# PIC32MX470F512H register map
Registers are 32-bit, access not given, reset 0x0 unless marked. A register's access mark holds for its fields unless they carry their own. Offsets are from the block's base; [hi:lo] are bit positions; {n}, {i} and the like mark numbered series; 'fields as' and 'values as' point back to an identical list.

## ADC10 — ADC10 peripheral
Base 0xBF809000
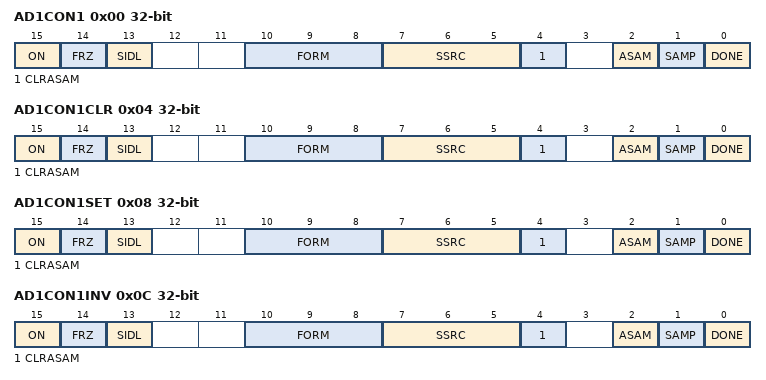
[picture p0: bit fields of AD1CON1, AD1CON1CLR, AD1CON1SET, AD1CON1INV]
0x00 AD1CON1
  [15] ON, [14] FRZ, [13] SIDL, [10:8] FORM, [7:5] SSRC, [4] CLRASAM, [2] ASAM, [1] SAMP, [0] DONE
0x04 AD1CON1CLR
  fields as AD1CON1
0x08 AD1CON1SET
  fields as AD1CON1
0x0C AD1CON1INV
  fields as AD1CON1
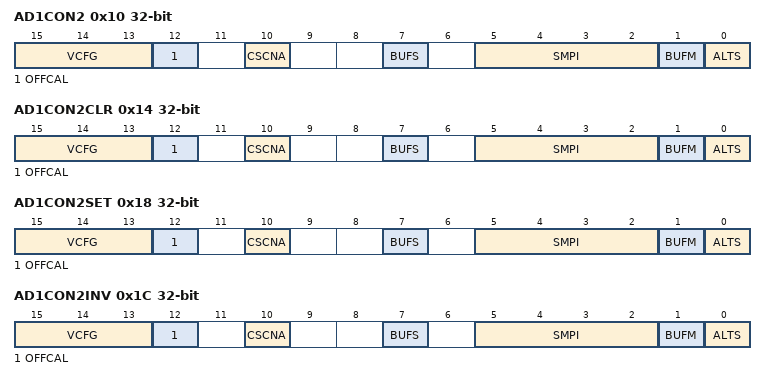
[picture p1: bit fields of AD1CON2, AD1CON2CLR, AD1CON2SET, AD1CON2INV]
0x10 AD1CON2
  [15:13] VCFG, [12] OFFCAL, [10] CSCNA, [7] BUFS, [5:2] SMPI, [1] BUFM, [0] ALTS
0x14 AD1CON2CLR
  fields as AD1CON2
0x18 AD1CON2SET
  fields as AD1CON2
0x1C AD1CON2INV
  fields as AD1CON2
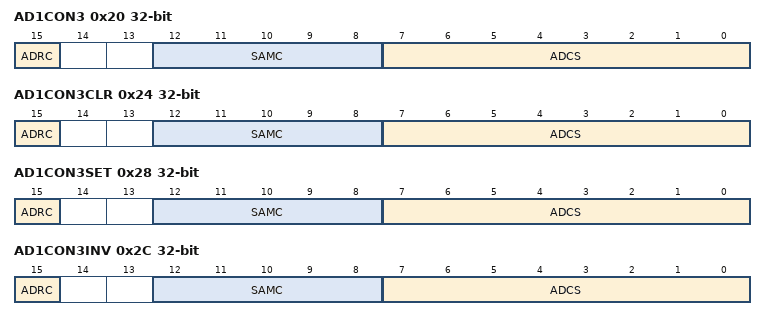
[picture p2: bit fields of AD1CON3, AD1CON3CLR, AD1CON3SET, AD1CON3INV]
0x20 AD1CON3
  [15] ADRC, [12:8] SAMC, [7:0] ADCS
0x24 AD1CON3CLR
  [15] ADRC, [12:8] SAMC, [7:0] ADCS
0x28 AD1CON3SET
  [15] ADRC, [12:8] SAMC, [7:0] ADCS
0x2C AD1CON3INV
  [15] ADRC, [12:8] SAMC, [7:0] ADCS
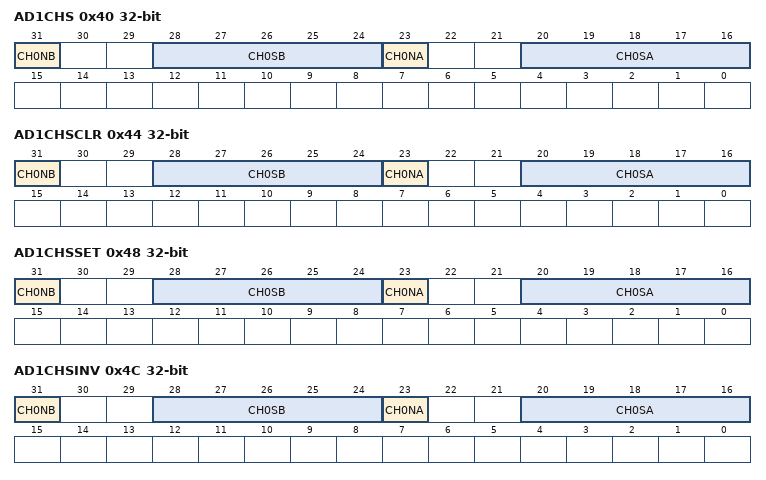
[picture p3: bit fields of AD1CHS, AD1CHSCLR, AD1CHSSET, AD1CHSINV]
0x40 AD1CHS
  [31] CH0NB, [28:24] CH0SB, [23] CH0NA, [20:16] CH0SA
0x44 AD1CHSCLR
  [31] CH0NB, [28:24] CH0SB, [23] CH0NA, [20:16] CH0SA
0x48 AD1CHSSET
  [31] CH0NB, [28:24] CH0SB, [23] CH0NA, [20:16] CH0SA
0x4C AD1CHSINV
  [31] CH0NB, [28:24] CH0SB, [23] CH0NA, [20:16] CH0SA
0x50 AD1CSSL
  [30:0] CSSL
0x54 AD1CSSLCLR
  [30:0] CSSL
0x58 AD1CSSLSET
  [30:0] CSSL
0x5C AD1CSSLINV
  [30:0] CSSL
{0x70+0x10*i} ADC1BUF{i} (i=0..9)
0x110 ADC1BUFA
0x120 ADC1BUFB
0x130 ADC1BUFC
0x140 ADC1BUFD
0x150 ADC1BUFE
0x160 ADC1BUFF

## CVR — CVR peripheral
Base 0xBF809800
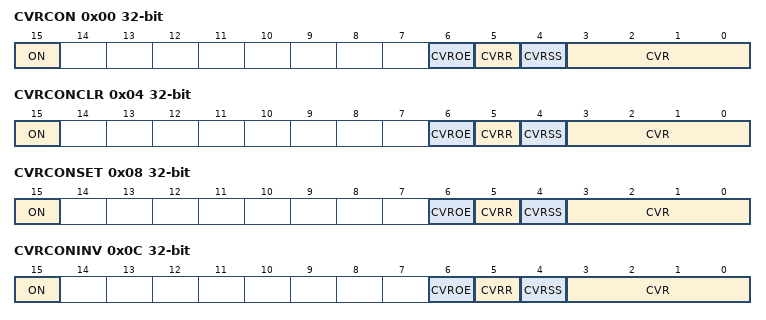
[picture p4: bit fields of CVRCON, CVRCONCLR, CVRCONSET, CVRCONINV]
0x00 CVRCON
  [15] ON, [6] CVROE, [5] CVRR, [4] CVRSS, [3:0] CVR
0x04 CVRCONCLR
  [15] ON, [6] CVROE, [5] CVRR, [4] CVRSS, [3:0] CVR
0x08 CVRCONSET
  [15] ON, [6] CVROE, [5] CVRR, [4] CVRSS, [3:0] CVR
0x0C CVRCONINV
  [15] ON, [6] CVROE, [5] CVRR, [4] CVRSS, [3:0] CVR

## CMP1 — CMP1 peripheral
Base 0xBF80A000
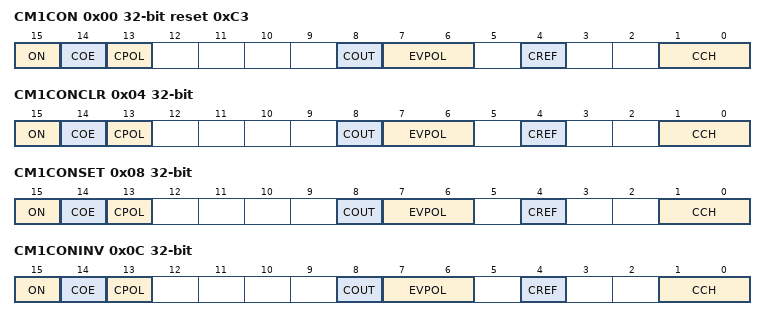
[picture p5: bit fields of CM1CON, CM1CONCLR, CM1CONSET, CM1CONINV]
0x00 CM1CON reset 0xC3
  [15] ON, [14] COE, [13] CPOL, [8] COUT, [7:6] EVPOL, [4] CREF, [1:0] CCH
0x04 CM1CONCLR
  fields as CM1CON
0x08 CM1CONSET
  fields as CM1CON
0x0C CM1CONINV
  fields as CM1CON

## CMP2 — CMP2 peripheral
Base 0xBF80A010
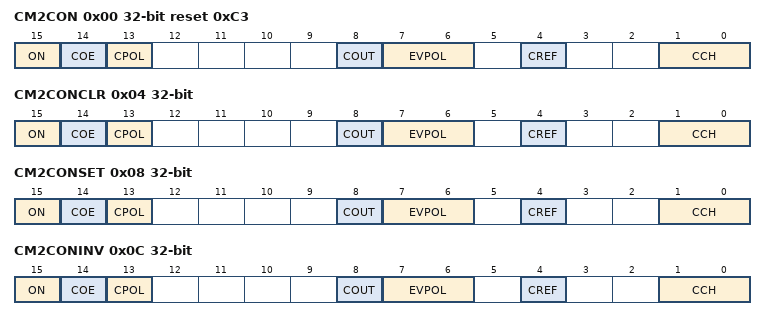
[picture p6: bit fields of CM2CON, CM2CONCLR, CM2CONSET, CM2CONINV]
0x00 CM2CON reset 0xC3
  [15] ON, [14] COE, [13] CPOL, [8] COUT, [7:6] EVPOL, [4] CREF, [1:0] CCH
0x04 CM2CONCLR
  fields as CM2CON
0x08 CM2CONSET
  fields as CM2CON
0x0C CM2CONINV
  fields as CM2CON

## CMP — CMP peripheral
Base 0xBF80A060
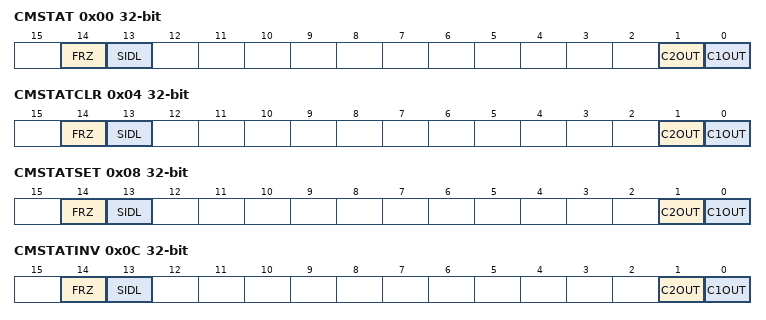
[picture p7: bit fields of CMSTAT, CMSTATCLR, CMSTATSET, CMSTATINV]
0x00 CMSTAT
  [14] FRZ, [13] SIDL, [1] C2OUT, [0] C1OUT
0x04 CMSTATCLR
  [14] FRZ, [13] SIDL, [1] C2OUT, [0] C1OUT
0x08 CMSTATSET
  [14] FRZ, [13] SIDL, [1] C2OUT, [0] C1OUT
0x0C CMSTATINV
  [14] FRZ, [13] SIDL, [1] C2OUT, [0] C1OUT

## CTMU — CTMU peripheral
Base 0xBF80A200
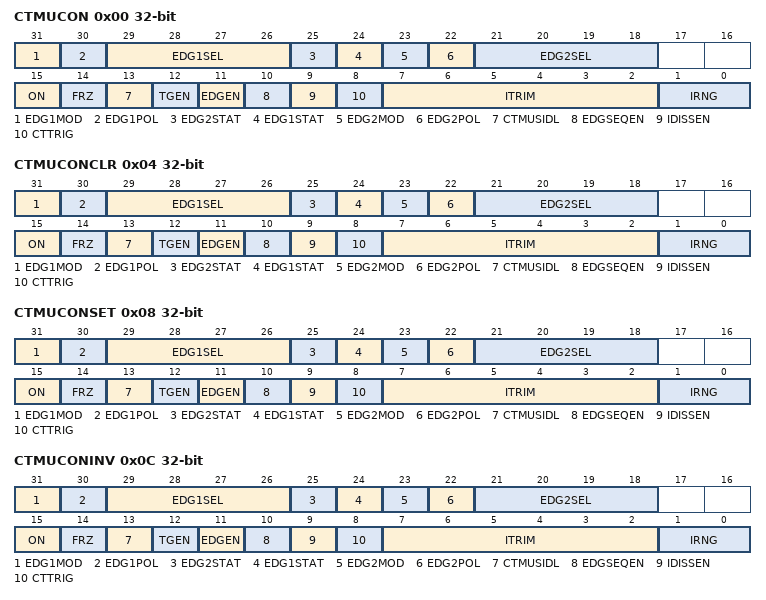
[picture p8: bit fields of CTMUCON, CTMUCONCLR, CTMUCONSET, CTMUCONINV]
0x00 CTMUCON
  [31] EDG1MOD, [30] EDG1POL, [29:26] EDG1SEL, [25] EDG2STAT, [24] EDG1STAT, [23] EDG2MOD, [22] EDG2POL, [21:18] EDG2SEL, [15] ON, [14] FRZ, [13] CTMUSIDL, [12] TGEN, [11] EDGEN, [10] EDGSEQEN, [9] IDISSEN, [8] CTTRIG, [7:2] ITRIM, [1:0] IRNG
0x04 CTMUCONCLR
  fields as CTMUCON
0x08 CTMUCONSET
  fields as CTMUCON
0x0C CTMUCONINV
  fields as CTMUCON

## OSC — OSC peripheral
Base 0xBF80F000
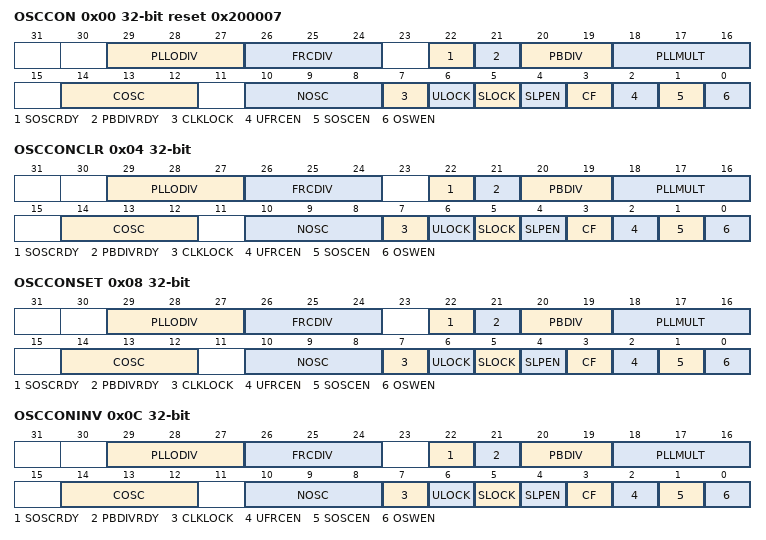
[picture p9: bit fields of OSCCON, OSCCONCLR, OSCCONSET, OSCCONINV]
0x00 OSCCON reset 0x200007
  [29:27] PLLODIV, [26:24] FRCDIV, [22] SOSCRDY, [21] PBDIVRDY, [20:19] PBDIV, [18:16] PLLMULT, [14:12] COSC, [10:8] NOSC, [7] CLKLOCK, [6] ULOCK, [5] SLOCK, [4] SLPEN, [3] CF, [2] UFRCEN, [1] SOSCEN, [0] OSWEN
0x04 OSCCONCLR
  fields as OSCCON
0x08 OSCCONSET
  fields as OSCCON
0x0C OSCCONINV
  fields as OSCCON
0x10 OSCTUN
  [5:0] TUN
0x14 OSCTUNCLR
  [5:0] TUN
0x18 OSCTUNSET
  [5:0] TUN
0x1C OSCTUNINV
  [5:0] TUN
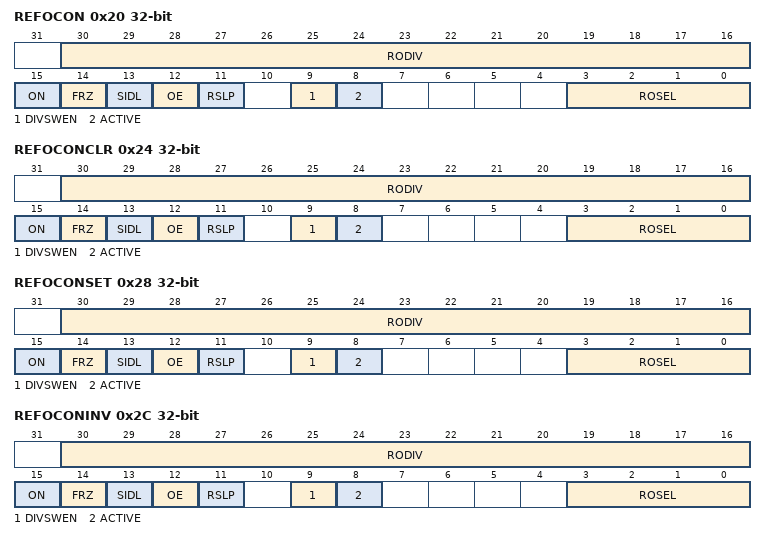
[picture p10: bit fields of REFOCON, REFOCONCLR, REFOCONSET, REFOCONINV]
0x20 REFOCON
  [30:16] RODIV, [15] ON, [14] FRZ, [13] SIDL, [12] OE, [11] RSLP, [9] DIVSWEN, [8] ACTIVE, [3:0] ROSEL
0x24 REFOCONCLR
  fields as REFOCON
0x28 REFOCONSET
  fields as REFOCON
0x2C REFOCONINV
  fields as REFOCON
0x30 REFOTRIM
  [31:23] ROTRIM
0x34 REFOTRIMCLR
  [31:23] ROTRIM
0x38 REFOTRIMSET
  [31:23] ROTRIM
0x3C REFOTRIMINV
  [31:23] ROTRIM

## CFG — CFG peripheral
Base 0xBF80F200
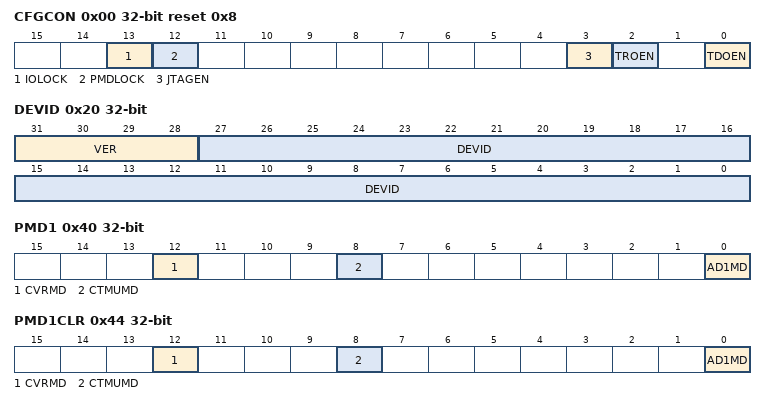
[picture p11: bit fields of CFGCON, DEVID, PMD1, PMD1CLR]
0x00 CFGCON reset 0x8
  [13] IOLOCK, [12] PMDLOCK, [3] JTAGEN, [2] TROEN, [0] TDOEN
0x20 DEVID
  [31:28] VER, [27:0] DEVID
0x30 SYSKEY
0x34 SYSKEYCLR
  [31:0] SYSKEY
0x38 SYSKEYSET
  [31:0] SYSKEY
0x3C SYSKEYINV
  [31:0] SYSKEY
0x40 PMD1
  [12] CVRMD, [8] CTMUMD, [0] AD1MD
0x44 PMD1CLR
  [12] CVRMD, [8] CTMUMD, [0] AD1MD
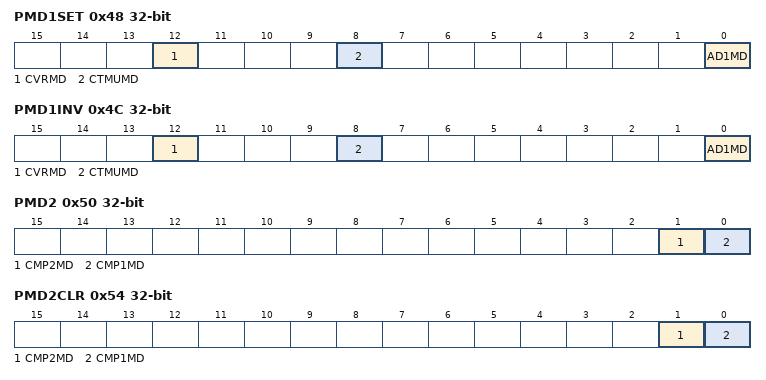
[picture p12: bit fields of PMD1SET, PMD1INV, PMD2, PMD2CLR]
0x48 PMD1SET
  [12] CVRMD, [8] CTMUMD, [0] AD1MD
0x4C PMD1INV
  [12] CVRMD, [8] CTMUMD, [0] AD1MD
0x50 PMD2
  [1] CMP2MD, [0] CMP1MD
0x54 PMD2CLR
  [1] CMP2MD, [0] CMP1MD
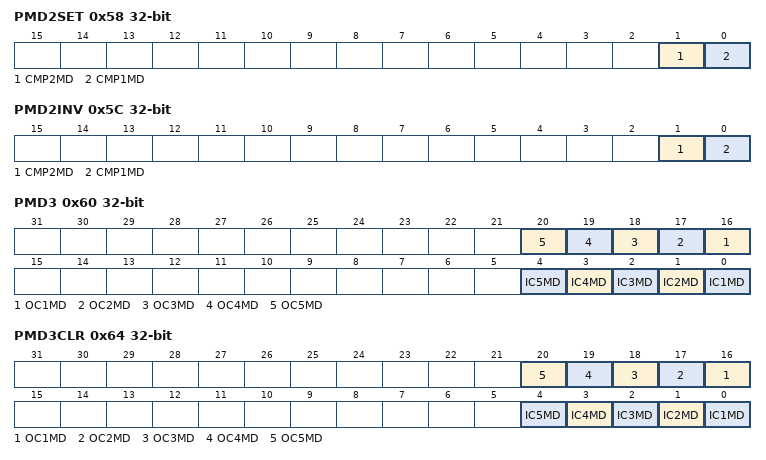
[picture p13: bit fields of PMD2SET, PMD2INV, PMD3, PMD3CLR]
0x58 PMD2SET
  [1] CMP2MD, [0] CMP1MD
0x5C PMD2INV
  [1] CMP2MD, [0] CMP1MD
0x60 PMD3
  [n+15] OC{n}MD (n=1..5), [n-1] IC{n}MD (n=1..5)
0x64 PMD3CLR
  [n+15] OC{n}MD (n=1..5), [n-1] IC{n}MD (n=1..5)
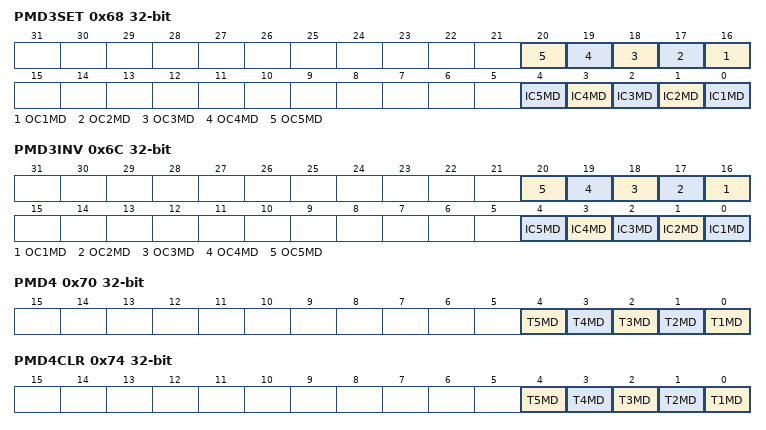
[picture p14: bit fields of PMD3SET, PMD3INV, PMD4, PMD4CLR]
0x68 PMD3SET
  [n+15] OC{n}MD (n=1..5), [n-1] IC{n}MD (n=1..5)
0x6C PMD3INV
  [n+15] OC{n}MD (n=1..5), [n-1] IC{n}MD (n=1..5)
0x70 PMD4
  [n-1] T{n}MD (n=1..5)
0x74 PMD4CLR
  [n-1] T{n}MD (n=1..5)
0x78 PMD4SET
  [n-1] T{n}MD (n=1..5)
0x7C PMD4INV
  [n-1] T{n}MD (n=1..5)
0x80 PMD5
  [24] USBMD, [17] I2C2MD, [16] I2C1MD, [9] SPI2MD, [8] SPI1MD, [n-1] U{n}MD (n=1..4)
0x84 PMD5CLR
  fields as PMD5
0x88 PMD5SET
  fields as PMD5
0x8C PMD5INV
  fields as PMD5
0x90 PMD6
  [16] PMPMD, [1] REFOMD, [0] RTCCMD
0x94 PMD6CLR
  [16] PMPMD, [1] REFOMD, [0] RTCCMD
0x98 PMD6SET
  [16] PMPMD, [1] REFOMD, [0] RTCCMD
0x9C PMD6INV
  [16] PMPMD, [1] REFOMD, [0] RTCCMD

## NVM — NVM peripheral
Base 0xBF80F400
0x00 NVMCON
  [15] WR, [14] WREN, [13] WRERR, [12] LVDERR, [11] LVDSTAT, [3:0] NVMOP
0x04 NVMCONCLR
  fields as NVMCON
0x08 NVMCONSET
  fields as NVMCON
0x0C NVMCONINV
  fields as NVMCON
0x10 NVMKEY
0x20 NVMADDR
0x24 NVMADDRCLR
  [31:0] NVMADDR
0x28 NVMADDRSET
  [31:0] NVMADDR
0x2C NVMADDRINV
  [31:0] NVMADDR
0x30 NVMDATA
0x40 NVMSRCADDR

## RCON — RCON peripheral
Base 0xBF80F600
0x00 RCON reset 0x3
  [29] HVDR, [9] CMR, [8] VREGS, [7] EXTR, [6] SWR, [4] WDTO, [3] SLEEP, [2] IDLE, [1] BOR, [0] POR
0x04 RCONCLR
  fields as RCON
0x08 RCONSET
  fields as RCON
0x0C RCONINV
  fields as RCON
0x10 RSWRST
  [0] SWRST
0x14 RSWRSTCLR
  [0] SWRST
0x18 RSWRSTSET
  [0] SWRST
0x1C RSWRSTINV
  [0] SWRST

## PPS — PPS peripheral
Base 0xBF80FA04
0x00 INT1R
  [3:0] INT1R
0x04 INT2R
  [3:0] INT2R
0x08 INT3R
  [3:0] INT3R
0x0C INT4R
  [3:0] INT4R
{0xC+4i} T{i}CKR (i=2..5)
  [3:0] T{i}CKR
{0x20+4i} IC{i}R (i=1..5)
  [3:0] IC{i}R
0x44 OCFAR
  [3:0] OCFAR
{0x44+8i} U{i}RXR (i=1..5)
  [3:0] U{i}RXR
{0x48+8i} U{i}CTSR (i=1..5)
  [3:0] U{i}CTSR
0x80 SDI1R
  [3:0] SDI1R
0x84 SS1R
  [3:0] SS1R
0x8C SDI2R
  [3:0] SDI2R
0x90 SS2R
  [3:0] SS2R
0xCC REFCLKIR
  [3:0] REFCLKIR
{0x13C+4i} RPB{i}R (i=0..3)
  [3:0] RPB{i}R
{0x13C+4i} RPB{i}R (i=5..10)
  [3:0] RPB{i}R
0x174 RPB14R
  [3:0] RPB14R
0x178 RPB15R
  [3:0] RPB15R
0x1B0 RPC13R
  [3:0] RPC13R
0x1B4 RPC14R
  [3:0] RPC14R
{0x1BC+4i} RPD{i}R (i=0..5)
  [3:0] RPD{i}R
{0x1BC+4i} RPD{i}R (i=8..11)
  [3:0] RPD{i}R
0x208 RPE3R
  [3:0] RPE3R
0x210 RPE5R
  [3:0] RPE5R
0x23C RPF0R
  [3:0] RPF0R
0x240 RPF1R
  [3:0] RPF1R
0x24C RPF4R
  [3:0] RPF4R
0x250 RPF5R
  [3:0] RPF5R
{0x27C+4i} RPG{i}R (i=6..9)
  [3:0] RPG{i}R
